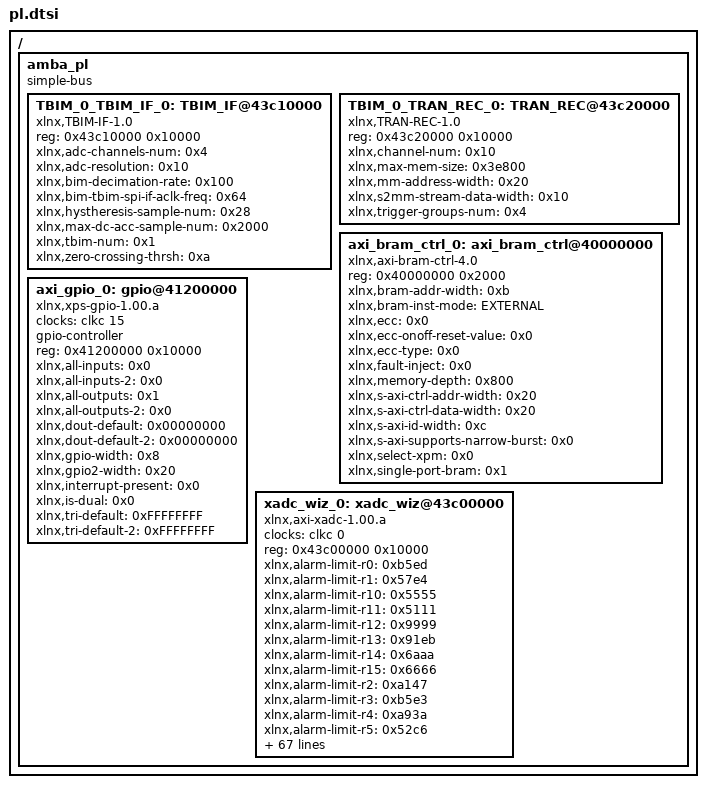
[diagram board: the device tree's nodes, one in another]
/*
 * CAUTION: This file is automatically generated by Xilinx.
 * Version:  
 * Today is: Mon Nov  5 11:40:35 2018
 */


/ {
	amba_pl: amba_pl {
		#address-cells = <1>;
		#size-cells = <1>;
		compatible = "simple-bus";
		ranges ;
		TBIM_0_TBIM_IF_0: TBIM_IF@43c10000 {
			compatible = "xlnx,TBIM-IF-1.0";
			reg = <0x43c10000 0x10000>;
			xlnx,adc-channels-num = <0x4>;
			xlnx,adc-resolution = <0x10>;
			xlnx,bim-decimation-rate = <0x100>;
			xlnx,bim-tbim-spi-if-aclk-freq = <0x64>;
			xlnx,hystheresis-sample-num = <0x28>;
			xlnx,max-dc-acc-sample-num = <0x2000>;
			xlnx,tbim-num = <0x1>;
			xlnx,zero-crossing-thrsh = <0xa>;
		};
		TBIM_0_TRAN_REC_0: TRAN_REC@43c20000 {
			compatible = "xlnx,TRAN-REC-1.0";
			reg = <0x43c20000 0x10000>;
			xlnx,channel-num = <0x10>;
			xlnx,max-mem-size = <0x3e800>;
			xlnx,mm-address-width = <0x20>;
			xlnx,s2mm-stream-data-width = <0x10>;
			xlnx,trigger-groups-num = <0x4>;
		};
		axi_bram_ctrl_0: axi_bram_ctrl@40000000 {
			compatible = "xlnx,axi-bram-ctrl-4.0";
			reg = <0x40000000 0x2000>;
			xlnx,bram-addr-width = <0xb>;
			xlnx,bram-inst-mode = "EXTERNAL";
			xlnx,ecc = <0x0>;
			xlnx,ecc-onoff-reset-value = <0x0>;
			xlnx,ecc-type = <0x0>;
			xlnx,fault-inject = <0x0>;
			xlnx,memory-depth = <0x800>;
			xlnx,s-axi-ctrl-addr-width = <0x20>;
			xlnx,s-axi-ctrl-data-width = <0x20>;
			xlnx,s-axi-id-width = <0xc>;
			xlnx,s-axi-supports-narrow-burst = <0x0>;
			xlnx,select-xpm = <0x0>;
			xlnx,single-port-bram = <0x1>;
		};
		axi_gpio_0: gpio@41200000 {
			#gpio-cells = <3>;
			clock-names = "s_axi_aclk";
			clocks = <&clkc 15>;
			compatible = "xlnx,xps-gpio-1.00.a";
			gpio-controller ;
			reg = <0x41200000 0x10000>;
			xlnx,all-inputs = <0x0>;
			xlnx,all-inputs-2 = <0x0>;
			xlnx,all-outputs = <0x1>;
			xlnx,all-outputs-2 = <0x0>;
			xlnx,dout-default = <0x00000000>;
			xlnx,dout-default-2 = <0x00000000>;
			xlnx,gpio-width = <0x8>;
			xlnx,gpio2-width = <0x20>;
			xlnx,interrupt-present = <0x0>;
			xlnx,is-dual = <0x0>;
			xlnx,tri-default = <0xFFFFFFFF>;
			xlnx,tri-default-2 = <0xFFFFFFFF>;
		};
		xadc_wiz_0: xadc_wiz@43c00000 {
			clock-names = "ref_clk";
			clocks = <&clkc 0>;
			compatible = "xlnx,axi-xadc-1.00.a";
			reg = <0x43c00000 0x10000>;
			xlnx,alarm-limit-r0 = <0xb5ed>;
			xlnx,alarm-limit-r1 = <0x57e4>;
			xlnx,alarm-limit-r10 = <0x5555>;
			xlnx,alarm-limit-r11 = <0x5111>;
			xlnx,alarm-limit-r12 = <0x9999>;
			xlnx,alarm-limit-r13 = <0x91eb>;
			xlnx,alarm-limit-r14 = <0x6aaa>;
			xlnx,alarm-limit-r15 = <0x6666>;
			xlnx,alarm-limit-r2 = <0xa147>;
			xlnx,alarm-limit-r3 = <0xb5e3>;
			xlnx,alarm-limit-r4 = <0xa93a>;
			xlnx,alarm-limit-r5 = <0x52c6>;
			xlnx,alarm-limit-r6 = <0x9555>;
			xlnx,alarm-limit-r7 = <0xae4e>;
			xlnx,alarm-limit-r8 = <0x5999>;
			xlnx,alarm-limit-r9 = <0x5111>;
			xlnx,configuration-r0 = <0x0>;
			xlnx,configuration-r1 = <0x21af>;
			xlnx,configuration-r2 = <0x400>;
			xlnx,dclk-frequency = <0x64>;
			xlnx,external-mux = "none";
			xlnx,external-mux-channel = "VP_VN";
			xlnx,external-muxaddr-enable = <0x0>;
			xlnx,fifo-depth = <0x7>;
			xlnx,has-axi = <0x1>;
			xlnx,has-axi4stream = <0x0>;
			xlnx,has-busy = <0x1>;
			xlnx,has-channel = <0x1>;
			xlnx,has-convst = <0x0>;
			xlnx,has-convstclk = <0x0>;
			xlnx,has-dclk = <0x1>;
			xlnx,has-drp = <0x0>;
			xlnx,has-eoc = <0x1>;
			xlnx,has-eos = <0x1>;
			xlnx,has-external-mux = <0x0>;
			xlnx,has-jtagbusy = <0x0>;
			xlnx,has-jtaglocked = <0x0>;
			xlnx,has-jtagmodified = <0x0>;
			xlnx,has-ot-alarm = <0x0>;
			xlnx,has-reset = <0x0>;
			xlnx,has-temp-bus = <0x0>;
			xlnx,has-user-temp-alarm = <0x0>;
			xlnx,has-vbram-alarm = <0x0>;
			xlnx,has-vccaux-alarm = <0x0>;
			xlnx,has-vccddro-alarm = <0x0>;
			xlnx,has-vccint-alarm = <0x0>;
			xlnx,has-vccpaux-alarm = <0x0>;
			xlnx,has-vccpint-alarm = <0x0>;
			xlnx,has-vn = <0x1>;
			xlnx,has-vp = <0x1>;
			xlnx,include-intr = <0x1>;
			xlnx,sampling-rate = "961538.4615384615";
			xlnx,sequence-r0 = <0x47e0>;
			xlnx,sequence-r1 = <0x0>;
			xlnx,sequence-r2 = <0x0>;
			xlnx,sequence-r3 = <0x0>;
			xlnx,sequence-r4 = <0x0>;
			xlnx,sequence-r5 = <0x0>;
			xlnx,sequence-r6 = <0x0>;
			xlnx,sequence-r7 = <0x0>;
			xlnx,sim-file-name = "design";
			xlnx,sim-file-rel-path = "./";
			xlnx,sim-file-sel = "Default";
			xlnx,vaux0 = <0x0>;
			xlnx,vaux1 = <0x0>;
			xlnx,vaux10 = <0x0>;
			xlnx,vaux11 = <0x0>;
			xlnx,vaux12 = <0x0>;
			xlnx,vaux13 = <0x0>;
			xlnx,vaux14 = <0x0>;
			xlnx,vaux15 = <0x0>;
			xlnx,vaux2 = <0x0>;
			xlnx,vaux3 = <0x0>;
			xlnx,vaux4 = <0x0>;
			xlnx,vaux5 = <0x0>;
			xlnx,vaux6 = <0x0>;
			xlnx,vaux7 = <0x0>;
			xlnx,vaux8 = <0x0>;
			xlnx,vaux9 = <0x0>;
		};
	};
};
